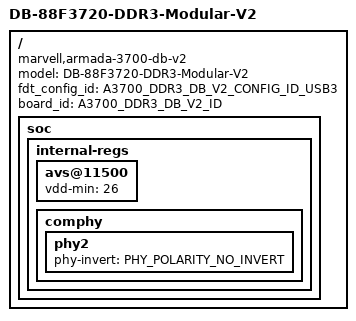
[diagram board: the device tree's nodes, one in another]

#include "armada-3700-ddr3-db.dts"

/* detail board setup:
 * Pcie Jumper slot	:	DB-88F3720-PCIe-mPCIe-Jumper
 * SGMII module slot	:	DB-88F3720-SerDes-Jumper
 * RGMII module slot	:	DB-88F3720-PHY module
 * eMMC slot		:	DB-88F3720-eMMC_NAND module
 * SDIO slot		:	DB-88F3720-SDcard module
 *
 * PHY0 (USB3/SGMII1)	:	USB3
 * PHY1 (PCIe/SGMII0)	:	PCIe (WiFi via mini_PCIe module)
 * PHY2 (SATA)		:	SATA
 * RGMII-0		:	Ethernet via PHY (1 Lane)
 * USB2 Port 0		:	USB2 as part USB3
 * USB2 Port 1		:	USB2 Host
 * eMMC*		:	eMMC NAND
 * SDIO*		:	SD card
 * BOOT device*		:	SPI Flash
*/

/ {
	model = "DB-88F3720-DDR3-Modular-V2";
	compatible = "marvell,armada-3700-db-v2", "marvell,armada-3700";
	fdt_config_id = <A3700_DDR3_DB_V2_CONFIG_ID_USB3>;
	board_id = <A3700_DDR3_DB_V2_ID>;

	soc {
		internal-regs {
			avs@11500 {
				vdd-min = <26>;
			};
			comphy {
				phy2 {
					phy-invert = <PHY_POLARITY_NO_INVERT>;
				};
			};
		};
	};
};
